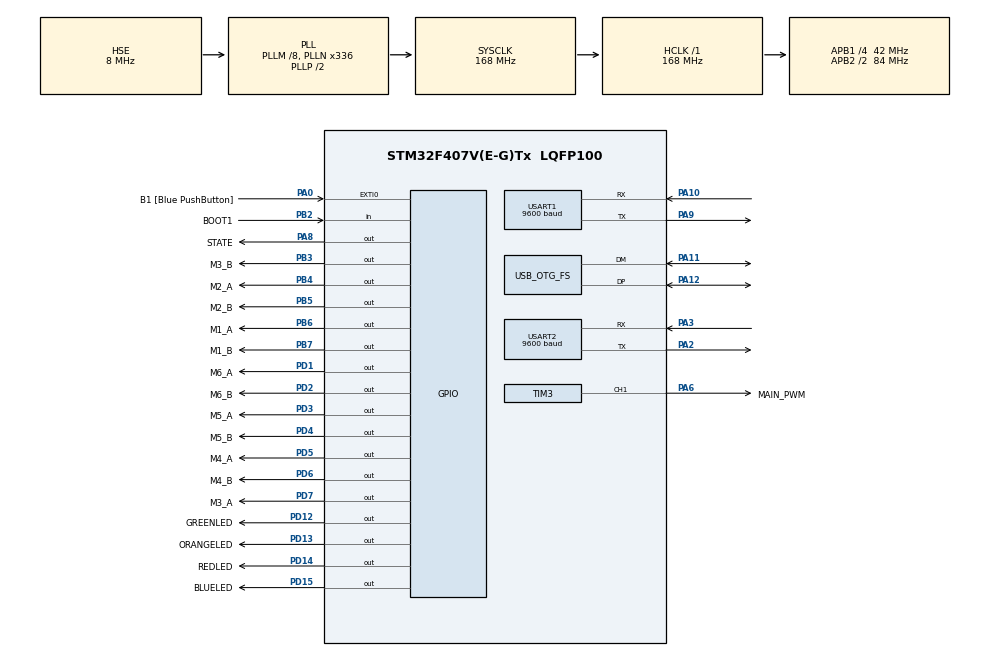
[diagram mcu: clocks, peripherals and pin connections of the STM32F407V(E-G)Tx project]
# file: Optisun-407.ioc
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Dma.Request0=USART2_RX
Dma.USART2_RX.0.Direction=DMA_PERIPH_TO_MEMORY
Dma.USART2_RX.0.FIFOMode=DMA_FIFOMODE_DISABLE
Dma.USART2_RX.0.Instance=DMA1_Stream5
Dma.USART2_RX.0.MemDataAlignment=DMA_MDATAALIGN_BYTE
Dma.USART2_RX.0.MemInc=DMA_MINC_ENABLE
Dma.USART2_RX.0.Mode=DMA_CIRCULAR
Dma.USART2_RX.0.PeriphDataAlignment=DMA_PDATAALIGN_BYTE
Dma.USART2_RX.0.PeriphInc=DMA_PINC_DISABLE
Dma.USART2_RX.0.Priority=DMA_PRIORITY_LOW
Mcu.Family=STM32F4
Mcu.Name=STM32F407V(E-G)Tx
Mcu.Package=LQFP100
NVIC.DMA1_Stream5_IRQn=true\:0\:0\:false\:false\:true\:false\:true\:true
NVIC.OTG_FS_IRQn=true\:0\:0\:false\:false\:true\:false\:true\:true
NVIC.PriorityGroup=NVIC_PRIORITYGROUP_0
NVIC.USART2_IRQn=true\:0\:0\:false\:false\:true\:true\:true\:true
PA0-WKUP.GPIO_Label=B1 [Blue PushButton]
PA0-WKUP.GPIO_ModeDefaultEXTI=GPIO_MODE_EVT_RISING
PA0-WKUP.GPIO_PuPd=GPIO_NOPULL
PA0-WKUP.Signal=GPXTI0
PA10.Mode=Asynchronous
PA10.Signal=USART1_RX
PA11.Mode=Device_Only
PA11.Signal=USB_OTG_FS_DM
PA12.Mode=Device_Only
PA12.Signal=USB_OTG_FS_DP
PA13.GPIO_Label=SWDIO
PA13.Mode=Serial_Wire
PA13.Signal=SYS_JTMS-SWDIO
PA14.GPIO_Label=SWCLK
PA14.Mode=Serial_Wire
PA14.Signal=SYS_JTCK-SWCLK
PA2.Mode=Asynchronous
PA2.Signal=USART2_TX
PA3.Mode=Asynchronous
PA3.Signal=USART2_RX
PA6.GPIO_Label=MAIN_PWM
PA6.Signal=S_TIM3_CH1
PA8.GPIO_Label=STATE
PA8.Signal=GPIO_Output
PA9.Mode=Asynchronous
PA9.Signal=USART1_TX
PB2.GPIO_Label=BOOT1
PB2.GPIO_Mode=GPIO_MODE_INPUT
PB2.GPIO_PuPd=GPIO_NOPULL
PB2.Signal=GPIO_Input
PB3.GPIO_Label=M3_B
PB3.Signal=GPIO_Output
PB4.GPIO_Label=M2_A
PB4.Signal=GPIO_Output
PB5.GPIO_Label=M2_B
PB5.Signal=GPIO_Output
PB6.GPIO_Label=M1_A
PB6.Signal=GPIO_Output
PB7.GPIO_Label=M1_B
PB7.Signal=GPIO_Output
PC14-OSC32_IN.GPIO_Label=PC14-OSC32_IN
PC14-OSC32_IN.Mode=LSE-External-Oscillator
PC14-OSC32_IN.Signal=RCC_OSC32_IN
PC15-OSC32_OUT.GPIO_Label=PC15-OSC32_OUT
PC15-OSC32_OUT.Mode=LSE-External-Oscillator
PC15-OSC32_OUT.Signal=RCC_OSC32_OUT
PC3.GPIO_Label=PDM_OUT [MP45DT02_DOUT]
PC3.GPIO_Mode=GPIO_MODE_AF_PP
PC3.GPIO_PuPd=GPIO_NOPULL
PC3.GPIO_Speed=GPIO_SPEED_FREQ_LOW
PC3.Signal=I2S2_SD
PD1.GPIO_Label=M6_A
PD1.Signal=GPIO_Output
PD12.GPIO_Label=GREENLED
PD12.GPIO_PuPd=GPIO_NOPULL
PD12.GPIO_Speed=GPIO_SPEED_FREQ_LOW
PD12.Signal=GPIO_Output
PD13.GPIO_Label=ORANGELED
PD13.GPIO_PuPd=GPIO_NOPULL
PD13.GPIO_Speed=GPIO_SPEED_FREQ_LOW
PD13.Signal=GPIO_Output
PD14.GPIO_Label=REDLED
PD14.GPIO_PuPd=GPIO_NOPULL
PD14.GPIO_Speed=GPIO_SPEED_FREQ_LOW
PD14.Signal=GPIO_Output
PD15.GPIO_Label=BLUELED
PD15.GPIO_PuPd=GPIO_NOPULL
PD15.GPIO_Speed=GPIO_SPEED_FREQ_LOW
PD15.Signal=GPIO_Output
PD2.GPIO_Label=M6_B
PD2.Signal=GPIO_Output
PD3.GPIO_Label=M5_A
PD3.Signal=GPIO_Output
PD4.GPIO_Label=M5_B
PD4.Signal=GPIO_Output
PD5.GPIO_Label=M4_A
PD5.Signal=GPIO_Output
PD6.GPIO_Label=M4_B
PD6.Signal=GPIO_Output
PD7.GPIO_Label=M3_A
PD7.Signal=GPIO_Output
PH0-OSC_IN.GPIO_Label=PH0-OSC_IN
PH0-OSC_IN.Mode=HSE-External-Oscillator
PH0-OSC_IN.Signal=RCC_OSC_IN
PH1-OSC_OUT.GPIO_Label=PH1-OSC_OUT
PH1-OSC_OUT.Mode=HSE-External-Oscillator
PH1-OSC_OUT.Signal=RCC_OSC_OUT
ProjectManager.HeapSize=0x200
ProjectManager.StackSize=0x400
ProjectManager.TargetToolchain=MDK-ARM V5.32
RCC.48MHZClocksFreq_Value=48000000
RCC.AHBFreq_Value=168000000
RCC.APB1CLKDivider=RCC_HCLK_DIV4
RCC.APB1Freq_Value=42000000
RCC.APB1TimFreq_Value=84000000
RCC.APB2CLKDivider=RCC_HCLK_DIV2
RCC.APB2Freq_Value=84000000
RCC.APB2TimFreq_Value=168000000
RCC.CortexFreq_Value=168000000
RCC.HCLKFreq_Value=168000000
RCC.HSE_VALUE=8000000
RCC.HSI_VALUE=16000000
RCC.PLLM=8
RCC.PLLN=336
RCC.PLLQ=7
RCC.SYSCLKFreq_VALUE=168000000
RCC.SYSCLKSource=RCC_SYSCLKSOURCE_PLLCLK
RCC.VCOOutputFreq_Value=336000000
SH.S_TIM3_CH1.0=TIM3_CH1,PWM Generation1 CH1
TIM3.AutoReloadPreload=TIM_AUTORELOAD_PRELOAD_ENABLE
TIM3.Channel-PWM\ Generation1\ CH1=TIM_CHANNEL_1
TIM3.Period=8000
TIM3.Prescaler=20
USART1.BaudRate=9600
USART1.Parity=PARITY_NONE
USART1.VirtualMode=VM_ASYNC
USART1.WordLength=WORDLENGTH_8B
USART2.BaudRate=9600
USART2.Parity=PARITY_NONE
USART2.VirtualMode=VM_ASYNC
USB_DEVICE.CLASS_NAME_FS=CDC
USB_DEVICE.PRODUCT_STRING_CDC_FS=STM32F407D-OPTISUN
USB_DEVICE.VirtualMode-CDC_FS=Cdc
USB_DEVICE.VirtualModeFS=Cdc_FS
USB_OTG_FS.VirtualMode=Device_Only
VP_USB_DEVICE_VS_USB_DEVICE_CDC_FS.Mode=CDC_FS
board=STM32F407G-DISC1

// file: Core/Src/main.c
/* USER CODE BEGIN Header */
/**
  ******************************************************************************
  * @file           : main.c
  * @brief          : Main program body
  ******************************************************************************
  * @attention
  *
  * Copyright (c) 2022 STMicroelectronics.
  * All rights reserved.
  *
  * This software is licensed under terms that can be found in the LICENSE file
  * in the root directory of this software component.
  * If no LICENSE file comes with this software, it is provided AS-IS.
  *
  ******************************************************************************
  */
/* USER CODE END Header */
#include "main.h"
#include "usb_device.h"

/* USER CODE BEGIN Includes */
#include "STInterface.h"
#include "MotorDriver.h"
#include "usbd_cdc_if.h"
#include<stdio.h>
#include<string.h>
/* USER CODE END Includes */

 TIM_HandleTypeDef htim3;

UART_HandleTypeDef huart1;
UART_HandleTypeDef huart2;
DMA_HandleTypeDef hdma_usart2_rx;

void SystemClock_Config(void);
static void MX_GPIO_Init(void);
static void MX_TIM3_Init(void);
static void MX_USART1_UART_Init(void);
static void MX_DMA_Init(void);
static void MX_USART2_UART_Init(void);

/* USER CODE BEGIN 0 */
void stringCallback(char* buffer,size_t length){
	_sti_sendString_(buffer,length);
}
/* USER CODE END 0 */

int main(void)
{

  /* MCU Configuration--------------------------------------------------------*/

  /* Reset of all peripherals, Initializes the Flash interface and the Systick. */
  HAL_Init();

  /* Configure the system clock */
  SystemClock_Config();

  /* Initialize all configured peripherals */
  MX_GPIO_Init();
  MX_TIM3_Init();
  MX_USART1_UART_Init();
  MX_DMA_Init();
  MX_USB_DEVICE_Init();
  MX_USART2_UART_Init();
  /* USER CODE BEGIN 2 */

  HAL_GPIO_WritePin(REDLED_GPIO_Port, REDLED_Pin, SET);
  sti_Setup_UART(&huart2);
  HAL_TIM_PWM_Start(&htim3, TIM_CHANNEL_1);
	sti_SetCallback_STRING(stringCallback);
  /* USER CODE END 2 */

  /* Infinite loop */
  while (1)
  {

    /* USER CODE BEGIN 3 */
		sti_resolveCommand();
		HAL_Delay(1000);

  }
  /* USER CODE END 3 */
}

void SystemClock_Config(void)
{
  RCC_OscInitTypeDef RCC_OscInitStruct = {0};
  RCC_ClkInitTypeDef RCC_ClkInitStruct = {0};

  /** Configure the main internal regulator output voltage
  */
  __HAL_RCC_PWR_CLK_ENABLE();
  __HAL_PWR_VOLTAGESCALING_CONFIG(PWR_REGULATOR_VOLTAGE_SCALE1);

  /** Initializes the RCC Oscillators according to the specified parameters
  * in the RCC_OscInitTypeDef structure.
  */
  RCC_OscInitStruct.OscillatorType = RCC_OSCILLATORTYPE_HSE;
  RCC_OscInitStruct.HSEState = RCC_HSE_ON;
  RCC_OscInitStruct.PLL.PLLState = RCC_PLL_ON;
  RCC_OscInitStruct.PLL.PLLSource = RCC_PLLSOURCE_HSE;
  RCC_OscInitStruct.PLL.PLLM = 8;
  RCC_OscInitStruct.PLL.PLLN = 336;
  RCC_OscInitStruct.PLL.PLLP = RCC_PLLP_DIV2;
  RCC_OscInitStruct.PLL.PLLQ = 7;
  if (HAL_RCC_OscConfig(&RCC_OscInitStruct) != HAL_OK)
  {
    Error_Handler();
  }

  /** Initializes the CPU, AHB and APB buses clocks
  */
  RCC_ClkInitStruct.ClockType = RCC_CLOCKTYPE_HCLK|RCC_CLOCKTYPE_SYSCLK
                              |RCC_CLOCKTYPE_PCLK1|RCC_CLOCKTYPE_PCLK2;
  RCC_ClkInitStruct.SYSCLKSource = RCC_SYSCLKSOURCE_PLLCLK;
  RCC_ClkInitStruct.AHBCLKDivider = RCC_SYSCLK_DIV1;
  RCC_ClkInitStruct.APB1CLKDivider = RCC_HCLK_DIV4;
  RCC_ClkInitStruct.APB2CLKDivider = RCC_HCLK_DIV2;

  if (HAL_RCC_ClockConfig(&RCC_ClkInitStruct, FLASH_LATENCY_5) != HAL_OK)
  {
    Error_Handler();
  }
}

static void MX_TIM3_Init(void)
{

  TIM_MasterConfigTypeDef sMasterConfig = {0};
  TIM_OC_InitTypeDef sConfigOC = {0};

  htim3.Instance = TIM3;
  htim3.Init.Prescaler = 20;
  htim3.Init.CounterMode = TIM_COUNTERMODE_UP;
  htim3.Init.Period = 8000;
  htim3.Init.ClockDivision = TIM_CLOCKDIVISION_DIV1;
  htim3.Init.AutoReloadPreload = TIM_AUTORELOAD_PRELOAD_ENABLE;
  if (HAL_TIM_PWM_Init(&htim3) != HAL_OK)
  {
    Error_Handler();
  }
  sMasterConfig.MasterOutputTrigger = TIM_TRGO_RESET;
  sMasterConfig.MasterSlaveMode = TIM_MASTERSLAVEMODE_DISABLE;
  if (HAL_TIMEx_MasterConfigSynchronization(&htim3, &sMasterConfig) != HAL_OK)
  {
    Error_Handler();
  }
  sConfigOC.OCMode = TIM_OCMODE_PWM1;
  sConfigOC.Pulse = 0;
  sConfigOC.OCPolarity = TIM_OCPOLARITY_HIGH;
  sConfigOC.OCFastMode = TIM_OCFAST_DISABLE;
  if (HAL_TIM_PWM_ConfigChannel(&htim3, &sConfigOC, TIM_CHANNEL_1) != HAL_OK)
  {
    Error_Handler();
  }
  HAL_TIM_MspPostInit(&htim3);

}

static void MX_USART1_UART_Init(void)
{

  huart1.Instance = USART1;
  huart1.Init.BaudRate = 9600;
  huart1.Init.WordLength = UART_WORDLENGTH_8B;
  huart1.Init.StopBits = UART_STOPBITS_1;
  huart1.Init.Parity = UART_PARITY_NONE;
  huart1.Init.Mode = UART_MODE_TX_RX;
  huart1.Init.HwFlowCtl = UART_HWCONTROL_NONE;
  huart1.Init.OverSampling = UART_OVERSAMPLING_16;
  if (HAL_UART_Init(&huart1) != HAL_OK)
  {
    Error_Handler();
  }

}

static void MX_USART2_UART_Init(void)
{

  huart2.Instance = USART2;
  huart2.Init.BaudRate = 9600;
  huart2.Init.WordLength = UART_WORDLENGTH_8B;
  huart2.Init.StopBits = UART_STOPBITS_1;
  huart2.Init.Parity = UART_PARITY_NONE;
  huart2.Init.Mode = UART_MODE_TX_RX;
  huart2.Init.HwFlowCtl = UART_HWCONTROL_NONE;
  huart2.Init.OverSampling = UART_OVERSAMPLING_16;
  if (HAL_UART_Init(&huart2) != HAL_OK)
  {
    Error_Handler();
  }

}

static void MX_DMA_Init(void)
{

  /* DMA controller clock enable */
  __HAL_RCC_DMA1_CLK_ENABLE();

  /* DMA interrupt init */
  /* DMA1_Stream5_IRQn interrupt configuration */
  HAL_NVIC_SetPriority(DMA1_Stream5_IRQn, 0, 0);
  HAL_NVIC_EnableIRQ(DMA1_Stream5_IRQn);

}

static void MX_GPIO_Init(void)
{
  GPIO_InitTypeDef GPIO_InitStruct = {0};

  /* GPIO Ports Clock Enable */
  __HAL_RCC_GPIOC_CLK_ENABLE();
  __HAL_RCC_GPIOH_CLK_ENABLE();
  __HAL_RCC_GPIOA_CLK_ENABLE();
  __HAL_RCC_GPIOB_CLK_ENABLE();
  __HAL_RCC_GPIOD_CLK_ENABLE();

  /*Configure GPIO pin Output Level */
  HAL_GPIO_WritePin(GPIOD, GREENLED_Pin|ORANGELED_Pin|REDLED_Pin|BLUELED_Pin
                          |M6_A_Pin|M6_B_Pin|M5_A_Pin|M5_B_Pin
                          |M4_A_Pin|M4_B_Pin|M3_A_Pin, GPIO_PIN_RESET);

  /*Configure GPIO pin Output Level */
  HAL_GPIO_WritePin(STATE_GPIO_Port, STATE_Pin, GPIO_PIN_RESET);

  /*Configure GPIO pin Output Level */
  HAL_GPIO_WritePin(GPIOB, M3_B_Pin|M2_A_Pin|M2_B_Pin|M1_A_Pin
                          |M1_B_Pin, GPIO_PIN_RESET);

  /*Configure GPIO pin : PDM_OUT_Pin */
  GPIO_InitStruct.Pin = PDM_OUT_Pin;
  GPIO_InitStruct.Mode = GPIO_MODE_AF_PP;
  GPIO_InitStruct.Pull = GPIO_NOPULL;
  GPIO_InitStruct.Speed = GPIO_SPEED_FREQ_LOW;
  GPIO_InitStruct.Alternate = GPIO_AF5_SPI2;
  HAL_GPIO_Init(PDM_OUT_GPIO_Port, &GPIO_InitStruct);

  /*Configure GPIO pin : B1_Pin */
  GPIO_InitStruct.Pin = B1_Pin;
  GPIO_InitStruct.Mode = GPIO_MODE_EVT_RISING;
  GPIO_InitStruct.Pull = GPIO_NOPULL;
  HAL_GPIO_Init(B1_GPIO_Port, &GPIO_InitStruct);

  /*Configure GPIO pin : BOOT1_Pin */
  GPIO_InitStruct.Pin = BOOT1_Pin;
  GPIO_InitStruct.Mode = GPIO_MODE_INPUT;
  GPIO_InitStruct.Pull = GPIO_NOPULL;
  HAL_GPIO_Init(BOOT1_GPIO_Port, &GPIO_InitStruct);

  /*Configure GPIO pins : GREENLED_Pin ORANGELED_Pin REDLED_Pin BLUELED_Pin
                           M6_A_Pin M6_B_Pin M5_A_Pin M5_B_Pin
                           M4_A_Pin M4_B_Pin M3_A_Pin */
  GPIO_InitStruct.Pin = GREENLED_Pin|ORANGELED_Pin|REDLED_Pin|BLUELED_Pin
                          |M6_A_Pin|M6_B_Pin|M5_A_Pin|M5_B_Pin
                          |M4_A_Pin|M4_B_Pin|M3_A_Pin;
  GPIO_InitStruct.Mode = GPIO_MODE_OUTPUT_PP;
  GPIO_InitStruct.Pull = GPIO_NOPULL;
  GPIO_InitStruct.Speed = GPIO_SPEED_FREQ_LOW;
  HAL_GPIO_Init(GPIOD, &GPIO_InitStruct);

  /*Configure GPIO pin : STATE_Pin */
  GPIO_InitStruct.Pin = STATE_Pin;
  GPIO_InitStruct.Mode = GPIO_MODE_OUTPUT_PP;
  GPIO_InitStruct.Pull = GPIO_NOPULL;
  GPIO_InitStruct.Speed = GPIO_SPEED_FREQ_LOW;
  HAL_GPIO_Init(STATE_GPIO_Port, &GPIO_InitStruct);

  /*Configure GPIO pins : M3_B_Pin M2_A_Pin M2_B_Pin M1_A_Pin
                           M1_B_Pin */
  GPIO_InitStruct.Pin = M3_B_Pin|M2_A_Pin|M2_B_Pin|M1_A_Pin
                          |M1_B_Pin;
  GPIO_InitStruct.Mode = GPIO_MODE_OUTPUT_PP;
  GPIO_InitStruct.Pull = GPIO_NOPULL;
  GPIO_InitStruct.Speed = GPIO_SPEED_FREQ_LOW;
  HAL_GPIO_Init(GPIOB, &GPIO_InitStruct);

}

void Error_Handler(void)
{
  __disable_irq();
  while (1)
  {
  }
}
